# qmss_qman register map
Vendor: Texas Instruments
Peripheral module from a debugger description file (folder Keystone2).
Registers are 32-bit, read-only, no defined reset value unless marked. A register's access mark holds for its fields unless they carry their own. Offsets are as the file gives them; lines under a group give offsets from that group; [hi:lo] are bit positions; {n}, {i} and the like mark numbered series; 'fields as' and 'values as' point back to an identical list; <NAME> marks a mode.

## QM_2_QMAN
0x00 QUEUE_REG_A — (1 of 8192, stride 16)
  [18:0] queue_entry_count — This field indicates how many packets are currently queued on the queue. This count is incremented by 1 whenever a packet is added to the queue. This count is decremented by 1 whenever a packet is popped from the queue.
0x04 QUEUE_REG_B — (1 of 8192, stride 16)
  [31:0] queue_byte_count — This field indicates how many bytes total are contained in all of the packets which are currently queued on this queue.
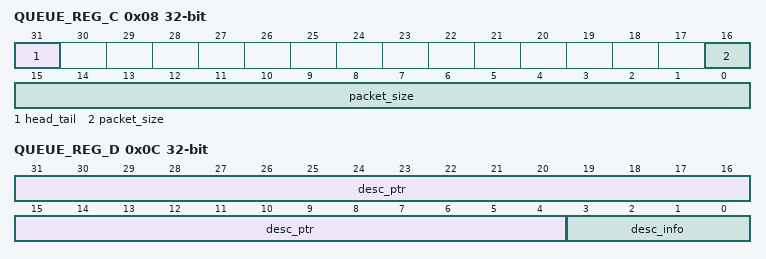
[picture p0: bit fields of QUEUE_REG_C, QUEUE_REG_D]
0x08 QUEUE_REG_C access per field — (1 of 8192, stride 16)
  [31] head_tail wo — Head/Tail Push Control. Set to zero in order to push packet onto tail of queue and set to one in order to push packet onto head of queue.
  [16:0] packet_size rw — This field indicates packet size and is assumed to be zero on each packet add unless the value is explicitly overwritten. This field indicates packet size for packet pop operation.
0x0C QUEUE_REG_D rw — (1 of 8192, stride 16)
  [31:4] desc_ptr — Descriptor pointer. It will be read as zero if the queue is empty. It will indicate a 32-bit aligned address that points to a descriptor when the queue is not empty.
  [3:0] desc_info — A generic value that is preserved during the push/pop cycle through the queue manager. This field will return a 0x0 when an empty queue is read.
